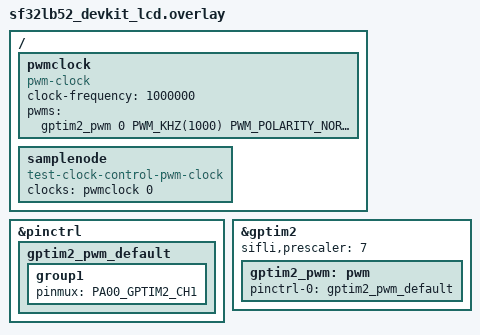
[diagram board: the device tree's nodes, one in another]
/*
 * Copyright (c) 2026 SiFli
 * SPDX-License-Identifier: Apache-2.0
 */

#include <zephyr/dt-bindings/pwm/pwm.h>

/ {
	pwmclock: pwmclock {
		status = "okay";
		compatible = "pwm-clock";
		#clock-cells = <1>;
		clock-frequency = <1000000>;
		pwms = <&gptim2_pwm 0 PWM_KHZ(1000) PWM_POLARITY_NORMAL>;
	};

	samplenode: samplenode {
		status = "okay";
		compatible = "test-clock-control-pwm-clock";
		clocks = <&pwmclock 0>;
	};
};

&pinctrl {
	gptim2_pwm_default: gptim2_pwm_default {
		group1 {
			pinmux = <PA00_GPTIM2_CH1>;
		};
	};
};

&gptim2 {
	status = "okay";
	sifli,prescaler = <7>;

	gptim2_pwm: pwm {
		status = "okay";
		pinctrl-0 = <&gptim2_pwm_default>;
		pinctrl-names = "default";
	};
};
